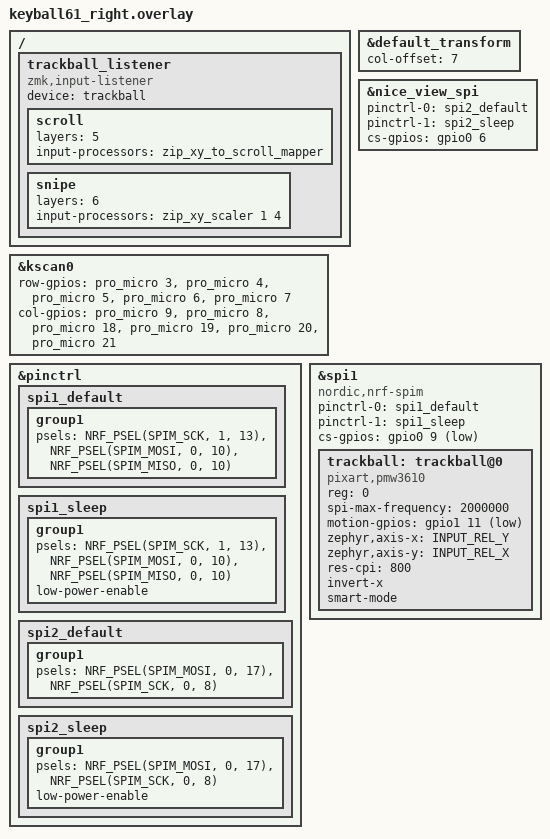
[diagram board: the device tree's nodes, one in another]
/*
 * Copyright (c) 2020 ZMK Contributors
 *
 * SPDX-License-Identifier: MIT
 */
 
#include <zephyr/dt-bindings/input/input-event-codes.h>
#include <input/processors.dtsi>
#include "keyball61.dtsi"

&default_transform {
    col-offset = <7>;
};

&kscan0 {
    row-gpios
        = <&pro_micro 3 (GPIO_ACTIVE_HIGH | GPIO_PULL_DOWN)>
        , <&pro_micro 4 (GPIO_ACTIVE_HIGH | GPIO_PULL_DOWN)>
        , <&pro_micro 5 (GPIO_ACTIVE_HIGH | GPIO_PULL_DOWN)>
        , <&pro_micro 6 (GPIO_ACTIVE_HIGH | GPIO_PULL_DOWN)>
        , <&pro_micro 7 (GPIO_ACTIVE_HIGH | GPIO_PULL_DOWN)>
        ;
    
	col-gpios
        = <&pro_micro 9  GPIO_ACTIVE_HIGH>
        , <&pro_micro 8  GPIO_ACTIVE_HIGH>
        , <&pro_micro 18 GPIO_ACTIVE_HIGH>
	    , <&pro_micro 19 GPIO_ACTIVE_HIGH>
		, <&pro_micro 20 GPIO_ACTIVE_HIGH>
		, <&pro_micro 21 GPIO_ACTIVE_HIGH>
		;
};

&pinctrl {
    spi1_default: spi1_default {
        group1 {
            psels = <NRF_PSEL(SPIM_SCK, 1, 13)>,
                    <NRF_PSEL(SPIM_MOSI, 0, 10)>,
                    <NRF_PSEL(SPIM_MISO, 0, 10)>;
        };
    };

    spi1_sleep: spi1_sleep {
        group1 {
            psels = <NRF_PSEL(SPIM_SCK, 1, 13)>,
                    <NRF_PSEL(SPIM_MOSI, 0, 10)>,
                    <NRF_PSEL(SPIM_MISO, 0, 10)>;
            low-power-enable;
        };
    };

    spi2_default: spi2_default {
        group1 {
            psels = <NRF_PSEL(SPIM_MOSI, 0, 17)>,
                    <NRF_PSEL(SPIM_SCK, 0, 8)>;
        };
    };

    spi2_sleep: spi2_sleep {
        group1 {
            psels = <NRF_PSEL(SPIM_MOSI, 0, 17)>,
                    <NRF_PSEL(SPIM_SCK, 0, 8)>;
            low-power-enable;
        };
    };
};

&nice_view_spi {
    pinctrl-0 = <&spi2_default>;
    pinctrl-1 = <&spi2_sleep>;
    pinctrl-names = "default", "sleep";
    cs-gpios = <&gpio0 6 (GPIO_ACTIVE_HIGH | GPIO_PULL_DOWN)>;
};


&spi1 {
    status = "okay";
    compatible = "nordic,nrf-spim";
    pinctrl-0 = <&spi1_default>;
    pinctrl-1 = <&spi1_sleep>;
    pinctrl-names = "default", "sleep";
    cs-gpios = <&gpio0 9 GPIO_ACTIVE_LOW>;

    trackball: trackball@0 {
        status = "okay";
        compatible = "pixart,pmw3610";
        reg = <0>;
        spi-max-frequency = <2000000>;
        motion-gpios = <&gpio1 11 (GPIO_ACTIVE_LOW | GPIO_PULL_UP)>;
        zephyr,axis-x = <INPUT_REL_Y>;
        zephyr,axis-y = <INPUT_REL_X>;
        res-cpi = <800>;
        invert-x;
        smart-mode;
    };
};

/ {
  trackball_listener {
    compatible = "zmk,input-listener";
    device = <&trackball>;

    scroll {
        layers = <5>;
        input-processors = <&zip_xy_to_scroll_mapper>;
    };

    snipe {
        layers = <6>;
        input-processors = <&zip_xy_scaler 1 4>;
    };
  };
};
